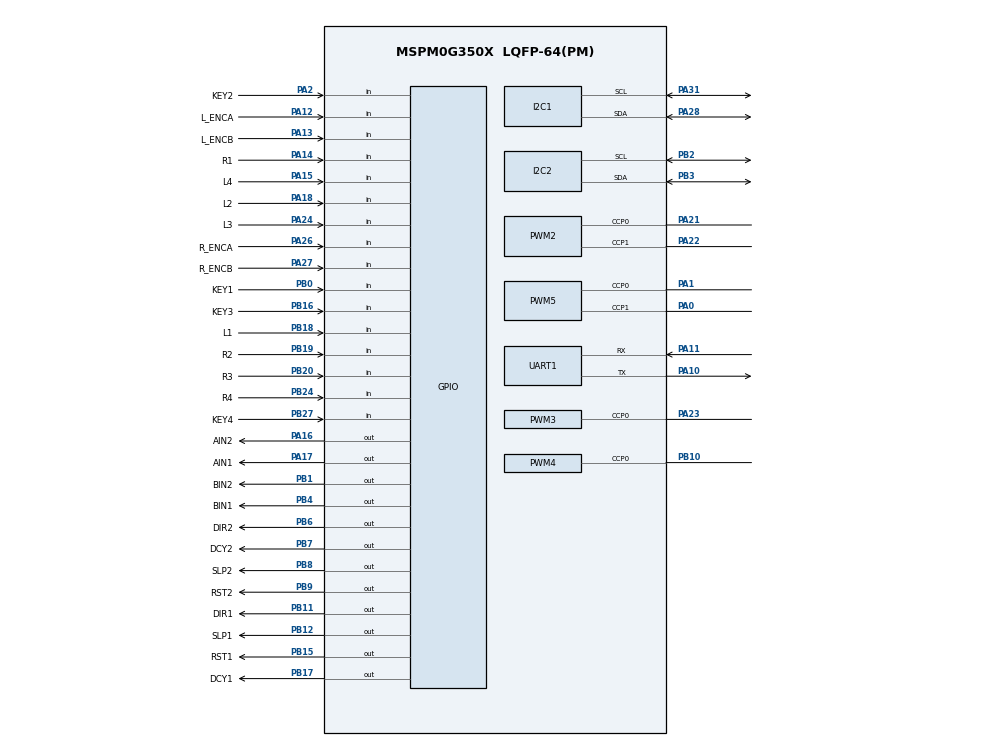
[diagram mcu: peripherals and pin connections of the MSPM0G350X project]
/**
 *
 * @cliArgs --device "MSPM0G350X" --part "Default" --package "LQFP-64(PM)" --product "mspm0_sdk@2.10.00.04"
 * @versions {"tool":"1.28.0+4696"}
 */

/**
 * Import the modules used in this configuration.
 */
const GPIO   = scripting.addModule("/ti/driverlib/GPIO", {}, false);
const GPIO1  = GPIO.addInstance();
const GPIO2  = GPIO.addInstance();
const GPIO3  = GPIO.addInstance();
const GPIO4  = GPIO.addInstance();
const GPIO5  = GPIO.addInstance();
const I2C    = scripting.addModule("/ti/driverlib/I2C", {}, false);
const I2C1   = I2C.addInstance();
const I2C2   = I2C.addInstance();
const PWM    = scripting.addModule("/ti/driverlib/PWM", {}, false);
const PWM1   = PWM.addInstance();
const PWM2   = PWM.addInstance();
const PWM3   = PWM.addInstance();
const PWM4   = PWM.addInstance();
const PWM5   = PWM.addInstance();
const SYSCTL = scripting.addModule("/ti/driverlib/SYSCTL");
const UART   = scripting.addModule("/ti/driverlib/UART", {}, false);
const UART1  = UART.addInstance();

/**
 * Write custom configuration values to the imported modules.
 */
const divider9       = system.clockTree["UDIV"];
divider9.divideValue = 2;

const multiplier2         = system.clockTree["PLL_QDIV"];
multiplier2.multiplyValue = 4;

const mux4       = system.clockTree["EXHFMUX"];
mux4.inputSelect = "EXHFMUX_XTAL";

const mux8       = system.clockTree["HSCLKMUX"];
mux8.inputSelect = "HSCLKMUX_SYSPLL0";

const mux12       = system.clockTree["SYSPLLMUX"];
mux12.inputSelect = "zSYSPLLMUX_HFCLK";

const pinFunction4     = system.clockTree["HFXT"];
pinFunction4.enable    = true;
pinFunction4.inputFreq = 40;

GPIO1.$name                         = "STEP_MOTOR";
GPIO1.associatedPins.create(8);
GPIO1.associatedPins[0].$name       = "DIR2";
GPIO1.associatedPins[0].pin.$assign = "PB6";
GPIO1.associatedPins[1].$name       = "DCY2";
GPIO1.associatedPins[1].pin.$assign = "PB7";
GPIO1.associatedPins[2].$name       = "SLP2";
GPIO1.associatedPins[2].pin.$assign = "PB8";
GPIO1.associatedPins[3].$name       = "RST2";
GPIO1.associatedPins[3].pin.$assign = "PB9";
GPIO1.associatedPins[4].$name       = "DIR1";
GPIO1.associatedPins[4].pin.$assign = "PB11";
GPIO1.associatedPins[5].$name       = "DCY1";
GPIO1.associatedPins[5].pin.$assign = "PB17";
GPIO1.associatedPins[6].$name       = "SLP1";
GPIO1.associatedPins[6].pin.$assign = "PB12";
GPIO1.associatedPins[7].$name       = "RST1";
GPIO1.associatedPins[7].pin.$assign = "PB15";

const Board = scripting.addModule("/ti/driverlib/Board", {}, false);

GPIO2.$name                         = "GRAY_SENSOR";
GPIO2.associatedPins.create(8);
GPIO2.associatedPins[0].$name       = "L4";
GPIO2.associatedPins[0].direction   = "INPUT";
GPIO2.associatedPins[0].pin.$assign = "PA15";
GPIO2.associatedPins[1].$name       = "L3";
GPIO2.associatedPins[1].direction   = "INPUT";
GPIO2.associatedPins[1].pin.$assign = "PA24";
GPIO2.associatedPins[2].$name       = "L2";
GPIO2.associatedPins[2].direction   = "INPUT";
GPIO2.associatedPins[2].pin.$assign = "PA18";
GPIO2.associatedPins[3].$name       = "L1";
GPIO2.associatedPins[3].direction   = "INPUT";
GPIO2.associatedPins[3].pin.$assign = "PB18";
GPIO2.associatedPins[4].$name       = "R1";
GPIO2.associatedPins[4].direction   = "INPUT";
GPIO2.associatedPins[4].pin.$assign = "PA14";
GPIO2.associatedPins[5].$name       = "R2";
GPIO2.associatedPins[5].direction   = "INPUT";
GPIO2.associatedPins[5].pin.$assign = "PB19";
GPIO2.associatedPins[6].$name       = "R3";
GPIO2.associatedPins[6].direction   = "INPUT";
GPIO2.associatedPins[6].pin.$assign = "PB20";
GPIO2.associatedPins[7].$name       = "R4";
GPIO2.associatedPins[7].direction   = "INPUT";
GPIO2.associatedPins[7].pin.$assign = "PB24";

GPIO3.$name                               = "DC_ENCODER";
GPIO3.associatedPins.create(4);
GPIO3.associatedPins[0].$name             = "L_ENCA";
GPIO3.associatedPins[0].direction         = "INPUT";
GPIO3.associatedPins[0].internalResistor  = "PULL_UP";
GPIO3.associatedPins[0].interruptEn       = true;
GPIO3.associatedPins[0].polarity          = "RISE_FALL";
GPIO3.associatedPins[0].interruptPriority = "0";
GPIO3.associatedPins[0].pin.$assign       = "PA12";
GPIO3.associatedPins[1].$name             = "L_ENCB";
GPIO3.associatedPins[1].direction         = "INPUT";
GPIO3.associatedPins[1].internalResistor  = "PULL_UP";
GPIO3.associatedPins[1].interruptEn       = true;
GPIO3.associatedPins[1].polarity          = "RISE_FALL";
GPIO3.associatedPins[1].interruptPriority = "0";
GPIO3.associatedPins[1].pin.$assign       = "PA13";
GPIO3.associatedPins[2].$name             = "R_ENCA";
GPIO3.associatedPins[2].direction         = "INPUT";
GPIO3.associatedPins[2].internalResistor  = "PULL_UP";
GPIO3.associatedPins[2].interruptEn       = true;
GPIO3.associatedPins[2].polarity          = "RISE_FALL";
GPIO3.associatedPins[2].interruptPriority = "0";
GPIO3.associatedPins[2].pin.$assign       = "PA26";
GPIO3.associatedPins[3].$name             = "R_ENCB";
GPIO3.associatedPins[3].direction         = "INPUT";
GPIO3.associatedPins[3].internalResistor  = "PULL_UP";
GPIO3.associatedPins[3].interruptEn       = true;
GPIO3.associatedPins[3].polarity          = "RISE_FALL";
GPIO3.associatedPins[3].interruptPriority = "0";
GPIO3.associatedPins[3].pin.$assign       = "PA27";

GPIO4.$name                         = "DC_MOTOR";
GPIO4.associatedPins.create(4);
GPIO4.associatedPins[0].$name       = "AIN1";
GPIO4.associatedPins[0].pin.$assign = "PA17";
GPIO4.associatedPins[1].$name       = "AIN2";
GPIO4.associatedPins[1].pin.$assign = "PA16";
GPIO4.associatedPins[2].$name       = "BIN1";
GPIO4.associatedPins[2].pin.$assign = "PB4";
GPIO4.associatedPins[3].$name       = "BIN2";
GPIO4.associatedPins[3].pin.$assign = "PB1";

GPIO5.$name                              = "KEY";
GPIO5.associatedPins.create(4);
GPIO5.associatedPins[0].$name            = "KEY1";
GPIO5.associatedPins[0].direction        = "INPUT";
GPIO5.associatedPins[0].internalResistor = "PULL_UP";
GPIO5.associatedPins[0].pin.$assign      = "PB0";
GPIO5.associatedPins[1].$name            = "KEY2";
GPIO5.associatedPins[1].direction        = "INPUT";
GPIO5.associatedPins[1].internalResistor = "PULL_UP";
GPIO5.associatedPins[1].pin.$assign      = "PA2";
GPIO5.associatedPins[2].$name            = "KEY3";
GPIO5.associatedPins[2].direction        = "INPUT";
GPIO5.associatedPins[2].internalResistor = "PULL_UP";
GPIO5.associatedPins[2].pin.$assign      = "PB16";
GPIO5.associatedPins[3].$name            = "KEY4";
GPIO5.associatedPins[3].internalResistor = "PULL_UP";
GPIO5.associatedPins[3].direction        = "INPUT";
GPIO5.associatedPins[3].pin.$assign      = "PB27";

I2C1.$name                             = "I2C_OLED";
I2C1.peripheral.sdaPin.$assign         = "PA28";
I2C1.peripheral.sclPin.$assign         = "PA31";
I2C1.sdaPinConfig.hideOutputInversion  = scripting.forceWrite(false);
I2C1.sdaPinConfig.onlyInternalResistor = scripting.forceWrite(false);
I2C1.sdaPinConfig.passedPeripheralType = scripting.forceWrite("Digital");
I2C1.sdaPinConfig.$name                = "ti_driverlib_gpio_GPIOPinGeneric9";
I2C1.sclPinConfig.hideOutputInversion  = scripting.forceWrite(false);
I2C1.sclPinConfig.onlyInternalResistor = scripting.forceWrite(false);
I2C1.sclPinConfig.passedPeripheralType = scripting.forceWrite("Digital");
I2C1.sclPinConfig.$name                = "ti_driverlib_gpio_GPIOPinGeneric10";

I2C2.$name                             = "I2C_MPU6050";
I2C2.basicEnableController             = true;
I2C2.peripheral.$assign                = "I2C1";
I2C2.peripheral.sdaPin.$assign         = "PB3";
I2C2.peripheral.sclPin.$assign         = "PB2";
I2C2.sdaPinConfig.hideOutputInversion  = scripting.forceWrite(false);
I2C2.sdaPinConfig.onlyInternalResistor = scripting.forceWrite(false);
I2C2.sdaPinConfig.passedPeripheralType = scripting.forceWrite("Digital");
I2C2.sdaPinConfig.$name                = "ti_driverlib_gpio_GPIOPinGeneric11";
I2C2.sclPinConfig.hideOutputInversion  = scripting.forceWrite(false);
I2C2.sclPinConfig.onlyInternalResistor = scripting.forceWrite(false);
I2C2.sclPinConfig.passedPeripheralType = scripting.forceWrite("Digital");
I2C2.sclPinConfig.$name                = "ti_driverlib_gpio_GPIOPinGeneric12";

PWM1.$name                              = "SERVO";
PWM1.clockDivider                       = 8;
PWM1.clockPrescale                      = 100;
PWM1.pwmMode                            = "EDGE_ALIGN_UP";
PWM1.ccIndex                            = [1];
PWM1.timerCount                         = 2000;
PWM1.timerStartTimer                    = true;
PWM1.ccp1PinConfig.direction            = scripting.forceWrite("OUTPUT");
PWM1.ccp1PinConfig.hideOutputInversion  = scripting.forceWrite(false);
PWM1.ccp1PinConfig.onlyInternalResistor = scripting.forceWrite(false);
PWM1.ccp1PinConfig.passedPeripheralType = scripting.forceWrite("Digital");
PWM1.ccp1PinConfig.$name                = "ti_driverlib_gpio_GPIOPinGeneric1";
PWM1.peripheral.$assign                 = "TIMG7";
PWM1.PWM_CHANNEL_1.$name                = "ti_driverlib_pwm_PWMTimerCC1";
PWM1.PWM_CHANNEL_1.dutyCycle            = 7.5;

PWM2.$name                              = "PWM";
PWM2.pwmMode                            = "EDGE_ALIGN_UP";
PWM2.clockPrescale                      = 2;
PWM2.timerCount                         = 10000;
PWM2.timerStartTimer                    = true;
PWM2.peripheral.$assign                 = "TIMA0";
PWM2.peripheral.ccp0Pin.$assign         = "PA21";
PWM2.peripheral.ccp1Pin.$assign         = "PA22";
PWM2.PWM_CHANNEL_0.$name                = "ti_driverlib_pwm_PWMTimerCC2";
PWM2.PWM_CHANNEL_1.$name                = "ti_driverlib_pwm_PWMTimerCC3";
PWM2.ccp0PinConfig.direction            = scripting.forceWrite("OUTPUT");
PWM2.ccp0PinConfig.hideOutputInversion  = scripting.forceWrite(false);
PWM2.ccp0PinConfig.onlyInternalResistor = scripting.forceWrite(false);
PWM2.ccp0PinConfig.passedPeripheralType = scripting.forceWrite("Digital");
PWM2.ccp0PinConfig.$name                = "ti_driverlib_gpio_GPIOPinGeneric4";
PWM2.ccp1PinConfig.direction            = scripting.forceWrite("OUTPUT");
PWM2.ccp1PinConfig.hideOutputInversion  = scripting.forceWrite(false);
PWM2.ccp1PinConfig.onlyInternalResistor = scripting.forceWrite(false);
PWM2.ccp1PinConfig.passedPeripheralType = scripting.forceWrite("Digital");
PWM2.ccp1PinConfig.$name                = "ti_driverlib_gpio_GPIOPinGeneric5";

PWM3.$name                              = "DCC_100_PWM2";
PWM3.ccIndex                            = [0];
PWM3.clockDivider                       = 8;
PWM3.timerCount                         = 10000;
PWM3.pwmMode                            = "EDGE_ALIGN_UP";
PWM3.PWM_CHANNEL_0.$name                = "ti_driverlib_pwm_PWMTimerCC4";
PWM3.PWM_CHANNEL_0.ccValue              = 50;
PWM3.ccp0PinConfig.direction            = scripting.forceWrite("OUTPUT");
PWM3.ccp0PinConfig.hideOutputInversion  = scripting.forceWrite(false);
PWM3.ccp0PinConfig.onlyInternalResistor = scripting.forceWrite(false);
PWM3.ccp0PinConfig.passedPeripheralType = scripting.forceWrite("Digital");
PWM3.ccp0PinConfig.$name                = "ti_driverlib_gpio_GPIOPinGeneric6";
PWM3.peripheral.$assign                 = "TIMG0";
PWM3.peripheral.ccp0Pin.$assign         = "PA23";

PWM4.$name                              = "DCC_100_PWM1";
PWM4.timerCount                         = 10000;
PWM4.pwmMode                            = "EDGE_ALIGN_UP";
PWM4.ccIndex                            = [0];
PWM4.clockDivider                       = 8;
PWM4.PWM_CHANNEL_0.$name                = "ti_driverlib_pwm_PWMTimerCC5";
PWM4.PWM_CHANNEL_0.ccValue              = 50;
PWM4.ccp0PinConfig.direction            = scripting.forceWrite("OUTPUT");
PWM4.ccp0PinConfig.hideOutputInversion  = scripting.forceWrite(false);
PWM4.ccp0PinConfig.onlyInternalResistor = scripting.forceWrite(false);
PWM4.ccp0PinConfig.passedPeripheralType = scripting.forceWrite("Digital");
PWM4.ccp0PinConfig.$name                = "ti_driverlib_gpio_GPIOPinGeneric2";
PWM4.peripheral.ccp0Pin.$assign         = "PB10";

PWM5.$name                              = "DC_MOTOR_PWM";
PWM5.timerCount                         = 10000;
PWM5.pwmMode                            = "EDGE_ALIGN_UP";
PWM5.timerStartTimer                    = true;
PWM5.peripheral.$assign                 = "TIMG8";
PWM5.peripheral.ccp0Pin.$assign         = "PA1";
PWM5.peripheral.ccp1Pin.$assign         = "PA0";
PWM5.PWM_CHANNEL_0.$name                = "ti_driverlib_pwm_PWMTimerCC0";
PWM5.PWM_CHANNEL_1.$name                = "ti_driverlib_pwm_PWMTimerCC6";
PWM5.ccp0PinConfig.direction            = scripting.forceWrite("OUTPUT");
PWM5.ccp0PinConfig.hideOutputInversion  = scripting.forceWrite(false);
PWM5.ccp0PinConfig.onlyInternalResistor = scripting.forceWrite(false);
PWM5.ccp0PinConfig.passedPeripheralType = scripting.forceWrite("Digital");
PWM5.ccp0PinConfig.$name                = "ti_driverlib_gpio_GPIOPinGeneric0";
PWM5.ccp1PinConfig.direction            = scripting.forceWrite("OUTPUT");
PWM5.ccp1PinConfig.hideOutputInversion  = scripting.forceWrite(false);
PWM5.ccp1PinConfig.onlyInternalResistor = scripting.forceWrite(false);
PWM5.ccp1PinConfig.passedPeripheralType = scripting.forceWrite("Digital");
PWM5.ccp1PinConfig.$name                = "ti_driverlib_gpio_GPIOPinGeneric3";

SYSCTL.enableWorkaround_SYSPLL_ERR_01 = false;
SYSCTL.clockTreeEn                    = true;
SYSCTL.SYSPLL_CLK0En                  = true;

UART1.$name                            = "vision_proto";
UART1.enabledInterrupts                = ["RX"];
UART1.targetBaudRate                   = 115200;
UART1.peripheral.$assign               = "UART0";
UART1.peripheral.rxPin.$assign         = "PA11";
UART1.peripheral.txPin.$assign         = "PA10";
UART1.txPinConfig.direction            = scripting.forceWrite("OUTPUT");
UART1.txPinConfig.hideOutputInversion  = scripting.forceWrite(false);
UART1.txPinConfig.onlyInternalResistor = scripting.forceWrite(false);
UART1.txPinConfig.passedPeripheralType = scripting.forceWrite("Digital");
UART1.txPinConfig.$name                = "ti_driverlib_gpio_GPIOPinGeneric7";
UART1.rxPinConfig.hideOutputInversion  = scripting.forceWrite(false);
UART1.rxPinConfig.onlyInternalResistor = scripting.forceWrite(false);
UART1.rxPinConfig.passedPeripheralType = scripting.forceWrite("Digital");
UART1.rxPinConfig.$name                = "ti_driverlib_gpio_GPIOPinGeneric8";

/**
 * Pinmux solution for unlocked pins/peripherals. This ensures that minor changes to the automatic solver in a future
 * version of the tool will not impact the pinmux you originally saw.  These lines can be completely deleted in order to
 * re-solve from scratch.
 */
pinFunction4.peripheral.$suggestSolution           = "SYSCTL";
pinFunction4.peripheral.hfxInPin.$suggestSolution  = "PA5";
pinFunction4.peripheral.hfxOutPin.$suggestSolution = "PA6";
Board.peripheral.$suggestSolution                  = "DEBUGSS";
Board.peripheral.swclkPin.$suggestSolution         = "PA20";
Board.peripheral.swdioPin.$suggestSolution         = "PA19";
I2C1.peripheral.$suggestSolution                   = "I2C0";
PWM1.peripheral.ccp1Pin.$suggestSolution           = "PA4";
PWM4.peripheral.$suggestSolution                   = "TIMG6";
